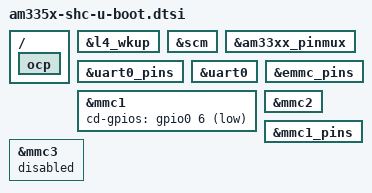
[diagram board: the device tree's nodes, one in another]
// SPDX-License-Identifier: GPL-2.0
/*
 * Copyright (C) 2019 Heiko Schocher <hs@denx.de>
 */

#include "am33xx-u-boot.dtsi"

/ {
	ocp {
		u-boot,dm-all;
	};
};

&l4_wkup {
	u-boot,dm-all;
};

&scm {
	u-boot,dm-all;
};

&am33xx_pinmux {
	u-boot,dm-all;
};

&uart0_pins {
	u-boot,dm-all;
};

&uart0 {
	u-boot,dm-all;
};

&mmc1 {
	u-boot,dm-all;
	cd-gpios = <&gpio0 6 GPIO_ACTIVE_LOW>;
};

&emmc_pins {
	u-boot,dm-all;
};

&mmc2 {
	u-boot,dm-all;
};

&mmc1_pins {
	u-boot,dm-all;
};

&mmc3 {
	status = "disabled";
};
